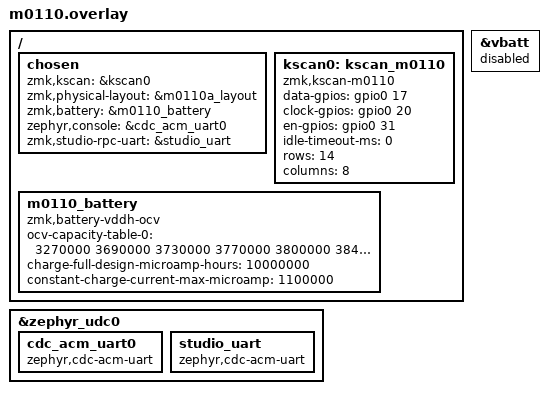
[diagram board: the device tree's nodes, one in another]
/*
 * M0110/M0110A Keyboard Converter Shield for nice!nano v2
 *
 * Pin connections:
 *   nice!nano D2 (P0.17) -> M0110 Data (directly to keyboard)
 *   nice!nano D3 (P0.20) -> M0110 Clock (directly to keyboard)
 *   nice!nano P0.31 ("031") -> bq25185 board boost EN pad
 *   bq25185 5V out        -> M0110 +5V
 *   nice!nano GND          -> M0110 GND
 *
 * The nice!nano communicates directly with the M0110 keyboard via
 * its SDA (D2) and SCL (D3) lines using the M0110 protocol.
 */

#include "m0110-layouts.dtsi"

/ {
    chosen {
        zmk,kscan = &kscan0;
        zmk,physical-layout = &m0110a_layout;
    };

    kscan0: kscan_m0110 {
        compatible = "zmk,kscan-m0110";
        status = "okay";

        /* nice!nano v2 Pro Micro compatible pinout
         * D2 (P0.17) = Data line (directly to keyboard)
         * D3 (P0.20) = Clock line (directly to keyboard)
         */
        data-gpios = <&gpio0 17 (GPIO_ACTIVE_HIGH | GPIO_PULL_UP)>;
        clock-gpios = <&gpio0 20 (GPIO_ACTIVE_HIGH | GPIO_PULL_UP)>;

        /* bq25185 board boost EN on P0.31.  The board pulls EN up (100k to
         * its VSYS), so the M0110 is powered unless this pin drives it low.
         * The driver holds it high and only drops it to power-cycle an
         * M0110 that has stopped answering (recover-timeout-ms). */
        en-gpios = <&gpio0 31 GPIO_ACTIVE_HIGH>;

        /* Power-save off.  Its only way back out is a key caught by one
         * INSTANT every few seconds, and with the M0110 unpowered a key
         * pressed in between is never seen at all.  After two idle days on
         * battery, BLE stayed connected but none of the typing reached ZMK. */
        idle-timeout-ms = <0>;

        /* Matrix dimensions for M0110A (14 rows x 8 cols = 112 positions) */
        rows = <14>;
        columns = <8>;
    };
};

/*
 * Battery gauge.  The board's stock &vbatt maps VDDH to percent with a straight
 * line and reads the charger's output, not the cell, while USB is plugged in.
 * See config/drivers/sensor/battery_estimator.c.  Both drivers use SAADC
 * channel 0, so the stock one must be disabled.
 */
&vbatt {
    status = "disabled";
};

/ {
    chosen {
        zmk,battery = &m0110_battery;
    };

    m0110_battery: m0110_battery {
        compatible = "zmk,battery-vddh-ocv";

        /* Typical LiPo resting voltage at 0%, 10%, ... 100% (Adafruit and
         * Ampow LiPo voltage charts).  Recalibrate from a logged discharge
         * if the readings drift from what the 10 Ah cell really does. */
        ocv-capacity-table-0 = <3270000 3690000 3730000 3770000 3800000 3840000
                                3870000 3950000 4020000 4110000 4200000>;

        /* 10 Ah cell.  One USB cable feeds both chargers: the bq25185 board
         * at its default 1 A and the nice!nano's own at about 100 mA. */
        charge-full-design-microamp-hours = <10000000>;
        constant-charge-current-max-microamp = <1100000>;
    };
};

/* USB CDC ACM for logging and Studio RPC */
&zephyr_udc0 {
    cdc_acm_uart0: cdc_acm_uart0 {
        compatible = "zephyr,cdc-acm-uart";
    };
    studio_uart: studio_uart {
        compatible = "zephyr,cdc-acm-uart";
    };
};

/ {
    chosen {
        zephyr,console = &cdc_acm_uart0;
        zmk,studio-rpc-uart = &studio_uart;
    };
};
